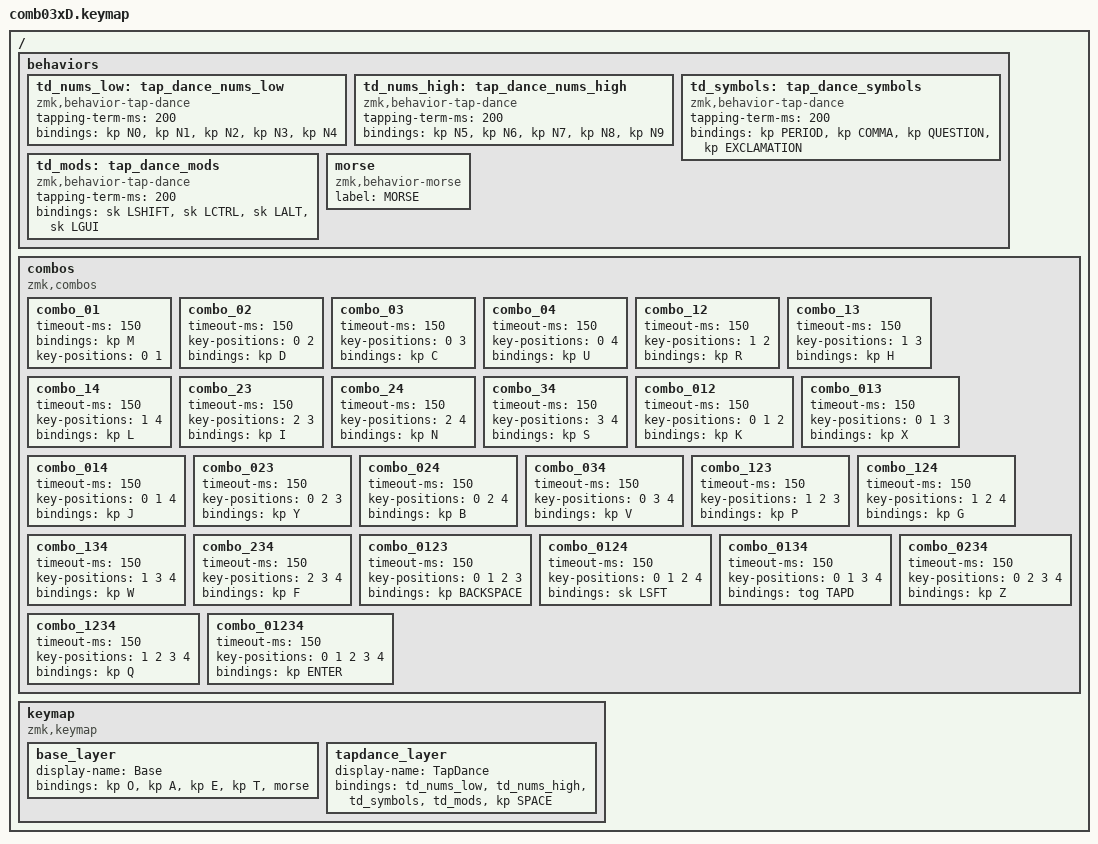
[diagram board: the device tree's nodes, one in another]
#include <behaviors.dtsi>
#include <dt-bindings/zmk/keys.h>

#define TAPD 1

/ {  

    behaviors {
        td_nums_low: tap_dance_nums_low {
            compatible = "zmk,behavior-tap-dance";
            #binding-cells = <0>;
            tapping-term-ms = <200>;
            bindings = <&kp N0>, <&kp N1>, <&kp N2>, <&kp N3>, <&kp N4>;
        };
        td_nums_high: tap_dance_nums_high {
            compatible = "zmk,behavior-tap-dance";
            #binding-cells = <0>;
            tapping-term-ms = <200>;
            bindings = <&kp N5>, <&kp N6>, <&kp N7>, <&kp N8>, <&kp N9>;
        };
        td_symbols: tap_dance_symbols {
            compatible = "zmk,behavior-tap-dance";
            #binding-cells = <0>;
            tapping-term-ms = <200>;
            bindings = <&kp PERIOD>, <&kp COMMA>, <&kp QUESTION>, <&kp EXCLAMATION>;
        };
        td_mods: tap_dance_mods {
            compatible = "zmk,behavior-tap-dance";
            #binding-cells = <0>;
            tapping-term-ms = <200>;
            bindings = <&sk LSHIFT>, <&sk LCTRL>, <&sk LALT>, <&sk LGUI>;
        };
        
        morse: morse {
            compatible = "zmk,behavior-morse";
            label = "MORSE";
            #binding-cells = <0>;
        };
    };

    combos {
        compatible = "zmk,combos";
        
        combo_01 {
            timeout-ms = <150>; // 150 ms to press all keys
            bindings = <&kp M>; // output of the combo
            key-positions = <0 1>; // keys used in combo
            // slow-release;   //Optional Released combo only when all keys are released
            // require-prior-idle-ms; // Required time after last non-modifier key press to trigger
        };
        
        combo_02 {
            timeout-ms = <150>;
            key-positions = <0 2>;
            bindings = <&kp D>;
        };
                
        combo_03 {
            timeout-ms = <150>;
            key-positions = <0 3>;
            bindings = <&kp C>;
        };
                
        combo_04 {
            timeout-ms = <150>;
            key-positions = <0 4>;
            bindings = <&kp U>;
        };
                
        combo_12 {
            timeout-ms = <150>;
            key-positions = <1 2>;
            bindings = <&kp R>;
        };
                
        combo_13 {
            timeout-ms = <150>;
            key-positions = <1 3>;
            bindings = <&kp H>;
        };
                
        combo_14 {
            timeout-ms = <150>;
            key-positions = <1 4>;
            bindings = <&kp L>;
        };
                
        combo_23 {
            timeout-ms = <150>;
            key-positions = <2 3>;
            bindings = <&kp I>;
        };
                
        combo_24 {
            timeout-ms = <150>;
            key-positions = <2 4>;
            bindings = <&kp N>;
        };
                
        combo_34 {
            timeout-ms = <150>;
            key-positions = <3 4>;
            bindings = <&kp S>;
        };
        
        combo_012 {
            timeout-ms = <150>;
            key-positions = <0 1 2>;
            bindings = <&kp K>;
        };
                
        combo_013 {
            timeout-ms = <150>;
            key-positions = <0 1 3>;
            bindings = <&kp X>;
        };
                
        combo_014 {
            timeout-ms = <150>;
            key-positions = <0 1 4>;
            bindings = <&kp J>;
        };
                
        combo_023 {
            timeout-ms = <150>;
            key-positions = <0 2 3>;
            bindings = <&kp Y>;
        };
                
        combo_024 {
            timeout-ms = <150>;
            key-positions = <0 2 4>;
            bindings = <&kp B>;
        };
                
        combo_034 {
            timeout-ms = <150>;
            key-positions = <0 3 4>;
            bindings = <&kp V>;
        };
                
        combo_123 {
            timeout-ms = <150>;
            key-positions = <1 2 3>;
            bindings = <&kp P>;
        };
                
        combo_124 {
            timeout-ms = <150>;
            key-positions = <1 2 4>;
            bindings = <&kp G>;
        };
                
        combo_134 {
            timeout-ms = <150>;
            key-positions = <1 3 4>;
            bindings = <&kp W>;
        };
                
        combo_234 {
            timeout-ms = <150>;
            key-positions = <2 3 4>;
            bindings = <&kp F>;
        };

        combo_0123 {
            timeout-ms = <150>;
            key-positions = <0 1 2 3>;
            bindings = <&kp BACKSPACE>;
        };
                
        combo_0124 {
            timeout-ms = <150>;
            key-positions = <0 1 2 4>;
            bindings = <&sk LSFT>;
        };
                
        combo_0134 {
            timeout-ms = <150>;
            key-positions = <0 1 3 4>;
            bindings = <&tog TAPD>;
        };
                
        combo_0234 {
            timeout-ms = <150>;
            key-positions = <0 2 3 4>;
            bindings = <&kp Z>;
        };
                
        combo_1234 {
            timeout-ms = <150>;
            key-positions = <1 2 3 4>;
            bindings = <&kp Q>;
        };
                
        combo_01234 {
            timeout-ms = <150>;
            key-positions = <0 1 2 3 4>;
            bindings = <&kp ENTER>;
        };
    };

    keymap {
        compatible = "zmk,keymap";

        base_layer {
            display-name = "Base";
//            bindings = < &kp O    &kp A    &kp E    &kp T   &kp SPACE >;
            bindings = < &kp O    &kp A    &kp E    &kp T   &morse >;
        };
        
        tapdance_layer {
            display-name = "TapDance";
            bindings = < &td_nums_low    &td_nums_high    &td_symbols    &td_mods   &kp SPACE >;
        };
    };
 };
